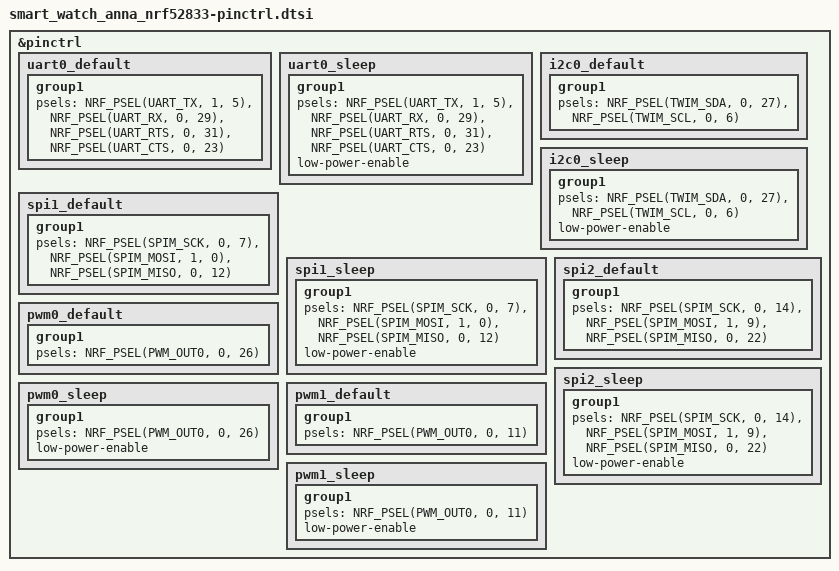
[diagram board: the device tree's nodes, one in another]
/*
 * Copyright (c) 2022 Nordic Semiconductor
 * SPDX-License-Identifier: Apache-2.0
 */

&pinctrl {
	// TODO remove for actual watch, no UART
	uart0_default: uart0_default {
		group1 {
			psels = <NRF_PSEL(UART_TX, 1, 5)>,
				<NRF_PSEL(UART_RX, 0, 29)>,
				<NRF_PSEL(UART_RTS, 0, 31)>,
				<NRF_PSEL(UART_CTS, 0, 23)>;
		};
	};

	uart0_sleep: uart0_sleep {
		group1 {
			psels = <NRF_PSEL(UART_TX, 1, 5)>,
				<NRF_PSEL(UART_RX, 0, 29)>,
				<NRF_PSEL(UART_RTS, 0, 31)>,
				<NRF_PSEL(UART_CTS, 0, 23)>;
			low-power-enable;
		};
	};

	i2c0_default: i2c0_default {
		group1 {
			psels = <NRF_PSEL(TWIM_SDA, 0, 27)>,
				<NRF_PSEL(TWIM_SCL, 0, 6)>;
		};
	};

	i2c0_sleep: i2c0_sleep {
		group1 {
			psels = <NRF_PSEL(TWIM_SDA, 0, 27)>,
				<NRF_PSEL(TWIM_SCL, 0, 6)>;
			low-power-enable;
		};
	};

	spi1_default: spi1_default {
		group1 {
			psels = <NRF_PSEL(SPIM_SCK, 0, 7)>,
				<NRF_PSEL(SPIM_MOSI, 1, 0)>,
				<NRF_PSEL(SPIM_MISO, 0, 12)>;
		};
	};

	spi1_sleep: spi1_sleep {
		group1 {
			psels = <NRF_PSEL(SPIM_SCK, 0, 7)>,
				<NRF_PSEL(SPIM_MOSI, 1, 0)>,
				<NRF_PSEL(SPIM_MISO, 0, 12)>;
			low-power-enable;
		};
	};

	spi2_default: spi2_default {
		group1 {
			psels = <NRF_PSEL(SPIM_SCK, 0, 14)>,
				<NRF_PSEL(SPIM_MOSI, 1, 9)>,
				<NRF_PSEL(SPIM_MISO, 0, 22)>;
		};
	};

	spi2_sleep: spi2_sleep {
		group1 {
			psels = <NRF_PSEL(SPIM_SCK, 0, 14)>,
				<NRF_PSEL(SPIM_MOSI, 1, 9)>,
				<NRF_PSEL(SPIM_MISO, 0, 22)>;
			low-power-enable;
		};
	};
	// Display BLK
	pwm0_default: pwm0_default {
		group1 {
			psels = <NRF_PSEL(PWM_OUT0, 0, 26)>;
		};
	};

	pwm0_sleep: pwm0_sleep {
		group1 {
			psels = <NRF_PSEL(PWM_OUT0, 0, 26)>;
			low-power-enable;
		};
	};

	// Vibration motor
	pwm1_default: pwm1_default {
		group1 {
			psels = <NRF_PSEL(PWM_OUT0, 0, 11)>;
		};
	};

	pwm1_sleep: pwm1_sleep {
		group1 {
			psels = <NRF_PSEL(PWM_OUT0, 0, 11)>;
			low-power-enable;
		};
	};

};
